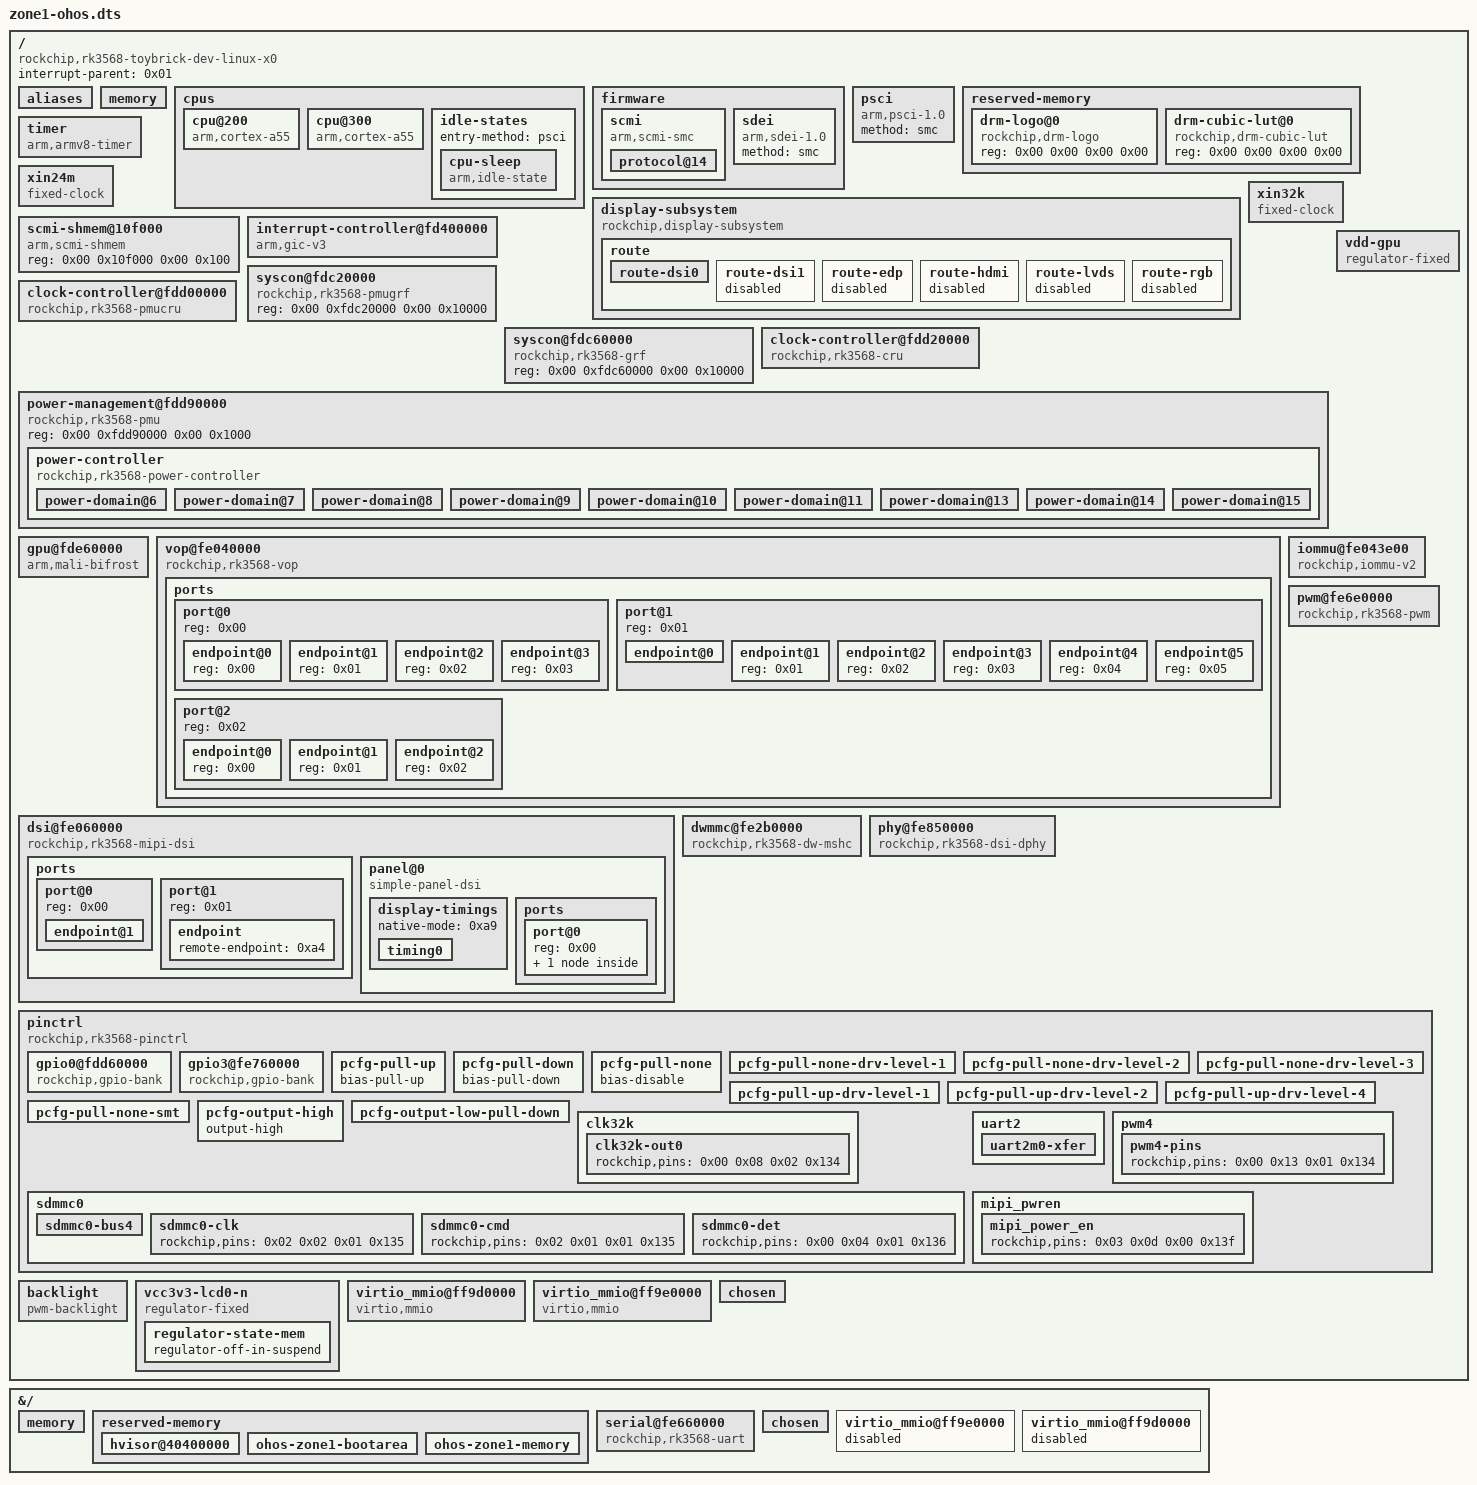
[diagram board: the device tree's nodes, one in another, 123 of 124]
/dts-v1/;

/ {
	interrupt-parent = <0x01>;
	#address-cells = <0x02>;
	#size-cells = <0x02>;
	compatible = "rockchip,rk3568-toybrick-dev-linux-x0\0rockchip,rk3568";

	aliases {
		dsi0 = "/dsi@fe060000";
		gpio3 = "/pinctrl/gpio3@fe760000";
		serial2 = "/serial@fe660000";
		mmc1 = "/dwmmc@fe2b0000";
	};

	memory {
		device_type = "memory";
		reg = <0x00 0x50000000 0x00 0x04000000 
		       0x00 0x10000000 0x00 0x20000000 
			   0x00 0x00 0x00 0x00 
			   0x00 0x00 0x00 0x00 
			   0x00 0x00 0x00 0x00 
			   0x00 0x00 0x00 0x00 
			   0x00 0x00 0x00 0x00 
			   0x00 0x00 0x00 0x00 
			   0x00 0x00 0x00 0x00 
			   0x00 0x00 0x00 0x00 
			   0x00 0x00 0x00 0x00 
			   0x00 0x00 0x00 0x00>;
	};

	cpus {
		#address-cells = <0x02>;
		#size-cells = <0x00>;

		// cpu@0 {
		// 	device_type = "cpu";
		// 	compatible = "arm,cortex-a55";
		// 	reg = <0x00 0x00>;
		// 	clocks = <0x02 0x00>;
		// 	#cooling-cells = <0x02>;
		// 	enable-method = "psci";
		// 	operating-points-v2 = <0x03>;
		// 	cpu-idle-states = <0x04>;
		// 	dynamic-power-coefficient = <0xbb>;
		// 	cpu-supply = <0x05>;
		// 	phandle = <0x1f>;
		// };

		// cpu@100 {
		// 	device_type = "cpu";
		// 	compatible = "arm,cortex-a55";
		// 	reg = <0x00 0x100>;
		// 	#cooling-cells = <0x02>;
		// 	enable-method = "psci";
		// 	operating-points-v2 = <0x03>;
		// 	cpu-idle-states = <0x04>;
		// 	phandle = <0x20>;
		// };

		cpu@200 {
			device_type = "cpu";
			compatible = "arm,cortex-a55";
			reg = <0x00 0x200>;
			#cooling-cells = <0x02>;
			enable-method = "psci";
			operating-points-v2 = <0x03>;
			cpu-idle-states = <0x04>;
			phandle = <0x21>;
		};

		cpu@300 {
			device_type = "cpu";
			compatible = "arm,cortex-a55";
			reg = <0x00 0x300>;
			#cooling-cells = <0x02>;
			enable-method = "psci";
			operating-points-v2 = <0x03>;
			cpu-idle-states = <0x04>;
			phandle = <0x22>;
		};

		idle-states {
			entry-method = "psci";

			cpu-sleep {
				compatible = "arm,idle-state";
				local-timer-stop;
				arm,psci-suspend-param = <0x10000>;
				entry-latency-us = <0x64>;
				exit-latency-us = <0x78>;
				min-residency-us = <0x3e8>;
				phandle = <0x04>;
			};
		};
	};

	firmware {

		scmi {
			compatible = "arm,scmi-smc";
			arm,smc-id = <0x82000010>;
			shmem = <0x19>;
			#address-cells = <0x01>;
			#size-cells = <0x00>;

			protocol@14 {
				reg = <0x14>;
				#clock-cells = <0x01>;
				rockchip,clk-init = <0x41cdb400>;
				phandle = <0x02>;
			};
		};

		sdei {
			compatible = "arm,sdei-1.0";
			method = "smc";
		};
	};

	psci {
		compatible = "arm,psci-1.0";
		method = "smc";
	};

	reserved-memory {
		#address-cells = <0x02>;
		#size-cells = <0x02>;
		ranges;

		drm-logo@0 {
			compatible = "rockchip,drm-logo";
			reg = <0x00 0x00 0x00 0x00>;
			phandle = <0x0f>;
		};

		drm-cubic-lut@0 {
			compatible = "rockchip,drm-cubic-lut";
			reg = <0x00 0x00 0x00 0x00>;
			phandle = <0x10>;
		};
	};

	display-subsystem {
		compatible = "rockchip,display-subsystem";
		memory-region = <0x0f 0x10>;
		memory-region-names = "drm-logo\0drm-cubic-lut";
		ports = <0x11>;

		route {

			route-dsi0 {
				status = "okay";
				logo,uboot = "logo.bmp";
				logo,kernel = "logo_kernel.bmp";
				logo,mode = "center";
				charge_logo,mode = "center";
				connect = <0x13>;
			};

			route-dsi1 {
				status = "disabled";
				logo,uboot = "logo.bmp";
				logo,kernel = "logo_kernel.bmp";
				logo,mode = "center";
				charge_logo,mode = "center";
				connect = <0x14>;
			};

			route-edp {
				status = "disabled";
				logo,uboot = "logo.bmp";
				logo,kernel = "logo_kernel.bmp";
				logo,mode = "center";
				charge_logo,mode = "center";
				connect = <0x15>;
			};

			route-hdmi {
				status = "disabled";
				logo,uboot = "logo.bmp";
				logo,kernel = "logo_kernel.bmp";
				logo,mode = "center";
				charge_logo,mode = "center";
				connect = <0x16>;
			};

			route-lvds {
				status = "disabled";
				logo,uboot = "logo.bmp";
				logo,kernel = "logo_kernel.bmp";
				logo,mode = "center";
				charge_logo,mode = "center";
				connect = <0x17>;
			};

			route-rgb {
				status = "disabled";
				logo,uboot = "logo.bmp";
				logo,kernel = "logo_kernel.bmp";
				logo,mode = "center";
				charge_logo,mode = "center";
				connect = <0x18>;
			};
		};
	};

	timer {
		compatible = "arm,armv8-timer";
		interrupts = <0x01 0x0d 0xf04 0x01 0x0e 0xf04 0x01 0x0b 0xf04 0x01 0x0a 0xf04>;
		arm,no-tick-in-suspend;
	};

	// important
	xin24m {
		compatible = "fixed-clock";
		clock-frequency = <0x16e3600>;
		clock-output-names = "xin24m";
		#clock-cells = <0x00>;
	};

	// important
	xin32k {
		compatible = "fixed-clock";
		clock-frequency = <0x8000>;
		clock-output-names = "xin32k";
		pinctrl-0 = <0x23>;
		pinctrl-names = "default";
		#clock-cells = <0x00>;
	};

	// important
	scmi-shmem@10f000 {
		compatible = "arm,scmi-shmem";
		reg = <0x00 0x10f000 0x00 0x100>;
		phandle = <0x19>;
	};

	interrupt-controller@fd400000 {
		compatible = "arm,gic-v3";
		#interrupt-cells = <0x03>;
		#address-cells = <0x02>;
		#size-cells = <0x02>;
		ranges;
		interrupt-controller;
		reg = <0x00 0xfd400000 0x00 0x10000 0x00 0xfd460000 0x00 0xc0000>;
		interrupts = <0x01 0x09 0x04>;
		phandle = <0x01>;
	};

	
	syscon@fdc20000 {
		compatible = "rockchip,rk3568-pmugrf\0syscon\0simple-mfd";
		reg = <0x00 0xfdc20000 0x00 0x10000>;
		phandle = <0x3c>;
	};

	syscon@fdc60000 {
		compatible = "rockchip,rk3568-grf\0syscon\0simple-mfd";
		reg = <0x00 0xfdc60000 0x00 0x10000>;
		phandle = <0x3b>;
	};

	
	clock-controller@fdd00000 {
		compatible = "rockchip,rk3568-pmucru";
		reg = <0x00 0xfdd00000 0x00 0x1000>;
		rockchip,grf = <0x3b>;
		rockchip,pmugrf = <0x3c>;
		#clock-cells = <0x01>;
		#reset-cells = <0x01>;
		assigned-clocks = <0x3a 0x32>;
		assigned-clock-parents = <0x3a 0x05>;
		phandle = <0x3a>;
	};

	clock-controller@fdd20000 {
		compatible = "rockchip,rk3568-cru";
		reg = <0x00 0xfdd20000 0x00 0x1000>;
		rockchip,grf = <0x3b>;
		#clock-cells = <0x01>;
		#reset-cells = <0x01>;
		assigned-clocks = <0x3a 0x05 0x24 0x106 0x24 0x10b 0x3a 0x01 0x3a 0x2b 0x24 0x03 0x24 0x19b 0x24 0x09 0x24 0x19c 0x24 0x19d 0x24 0x1a1 0x24 0x19e 0x24 0x19f 0x24 0x1a0 0x24 0x04 0x24 0x10d 0x24 0x10e 0x24 0x173 0x24 0x174 0x24 0x175 0x24 0x176 0x24 0xc9 0x24 0xca 0x24 0x06 0x24 0x7e 0x24 0x7f 0x24 0x3d 0x24 0x41 0x24 0x45 0x24 0x49 0x24 0x4d 0x24 0x4d 0x24 0x55 0x24 0x51 0x24 0x5d 0x24 0xdd>;
		assigned-clock-rates = <0x8000 0x11e1a300 0x11e1a300 0xbebc200 0x5f5e100 0x3b9aca00 0x1dcd6500 0x13d92d40 0xee6b280 0x7735940 0x5f5e100 0x3b9aca0 0x2faf080 0x17d7840 0x46cf7100 0x8f0d180 0x5f5e100 0x1dcd6500 0x17d78400 0x8f0d180 0x5f5e100 0x11e1a300 0x8f0d180 0x47868c00 0x17d78400 0x5f5e100 0x46cf7100 0x46cf7100 0x46cf7100 0x46cf7100 0x46cf7100 0x46cf7100 0x46cf7100 0x46cf7100 0x46cf7100 0x1dcd6500>;
		assigned-clock-parents = <0x3a 0x08 0x24 0x04 0x24 0x04>;
		phandle = <0x24>;
	};

	power-management@fdd90000 {
		compatible = "rockchip,rk3568-pmu\0syscon\0simple-mfd";
		reg = <0x00 0xfdd90000 0x00 0x1000>;

		power-controller {
			compatible = "rockchip,rk3568-power-controller";
			#power-domain-cells = <0x01>;
			#address-cells = <0x01>;
			#size-cells = <0x00>;
			phandle = <0x26>;

			power-domain@6 {
				reg = <0x06>;
				clocks = <0x24 0x27 0x24 0x25 0x24 0x26>;
				pm_qos = <0x4e>;
			};

			power-domain@7 {
				reg = <0x07>;
				clocks = <0x24 0x19 0x24 0x1a>;
				pm_qos = <0x4f>;
				#power-domain-cells = <0x00>;
			};

			power-domain@8 {
				reg = <0x08>;
				clocks = <0x24 0xcc 0x24 0xcd>;
				pm_qos = <0x50 0x51 0x52>;
				#power-domain-cells = <0x00>;
			};

			power-domain@9 {
				reg = <0x09>;
				clocks = <0x24 0xda 0x24 0xdb 0x24 0xdc>;
				pm_qos = <0x53 0x54 0x55>;
				#power-domain-cells = <0x00>;
			};

			power-domain@10 {
				reg = <0x0a>;
				clocks = <0x24 0xf1 0x24 0xf2>;
				pm_qos = <0x56 0x57 0x58 0x59 0x5a 0x5b>;
				#power-domain-cells = <0x00>;
			};

			power-domain@11 {
				reg = <0x0b>;
				clocks = <0x24 0xed>;
				pm_qos = <0x5c>;
				#power-domain-cells = <0x00>;
			};

			power-domain@13 {
				clocks = <0x24 0x107>;
				reg = <0x0d>;
				pm_qos = <0x5d>;
				#power-domain-cells = <0x00>;
			};

			power-domain@14 {
				reg = <0x0e>;
				clocks = <0x24 0x102>;
				pm_qos = <0x5e 0x5f 0x60>;
				#power-domain-cells = <0x00>;
			};

			power-domain@15 {
				reg = <0x0f>;
				clocks = <0x24 0x7f>;
				pm_qos = <0x61 0x62 0x63 0x64 0x65 0x66 0x67 0x68>;
				#power-domain-cells = <0x00>;
			};
		};
	};

	vdd-gpu {
		compatible = "regulator-fixed";
		regulator-name = "vdd_gpu";
		regulator-always-on;
		regulator-boot-on;
		regulator-min-microvolt = <0xdbba0>;
		regulator-max-microvolt = <0xdbba0>;
		phandle = <0x71>;
	};

	gpu@fde60000 {
		compatible = "arm,mali-bifrost";
		reg = <0x00 0xfde60000 0x00 0x4000>;
		interrupts = <0x00 0x27 0x04 0x00 0x29 0x04 0x00 0x28 0x04>;
		interrupt-names = "GPU\0MMU\0JOB";
		upthreshold = <0x28>;
		downdifferential = <0x0a>;
		clocks = <0x02 0x01 0x24 0x1b>;
		clock-names = "clk_mali\0clk_gpu";
		power-domains = <0x26 0x07>;
		#cooling-cells = <0x02>;
		status = "okay";
		mali-supply = <0x71>;
		phandle = <0x11e>;
	};

	vop@fe040000 {
		compatible = "rockchip,rk3568-vop";
		reg = <0x00 0xfe040000 0x00 0x3000 0x00 0xfe044000 0x00 0x1000>;
		reg-names = "regs\0gamma_lut";
		interrupts = <0x00 0x94 0x04>;
		clocks = <0x24 0xdd 0x24 0xde 0x24 0xdf 0x24 0xe0 0x24 0xe1>;
		clock-names = "aclk_vop\0hclk_vop\0dclk_vp0\0dclk_vp1\0dclk_vp2";
		rockchip,aclk-normal-mode-rates = <0x179a7b00>;
		rockchip,aclk-advanced-mode-rates = <0x1dcd6500>;
		iommus = <0x95>;
		power-domains = <0x26 0x09>;
		rockchip,grf = <0x3b>;
		status = "okay";
		assigned-clocks = <0x24 0xdf 0x24 0xe0>;
		assigned-clock-parents = <0x3a 0x02 0x24 0x05>;
		disable-afbc-win;

			ports {
			#address-cells = <0x01>;
			#size-cells = <0x00>;
			phandle = <0x11>;

			port@0 {
				reg = <0x00>;
				#address-cells = <0x01>;
				#size-cells = <0x00>;

				endpoint@0 {
					reg = <0x00>;
					phandle = <0xa3>;
				};

				endpoint@1 {
					reg = <0x01>;
					phandle = <0x14>;
				};

				endpoint@2 {
					reg = <0x02>;
					phandle = <0x15>;
				};

				endpoint@3 {
					reg = <0x03>;
					phandle = <0x16>;
				};
			};

			port@1 {
				reg = <0x01>;
				#address-cells = <0x01>;
				#size-cells = <0x00>;

				endpoint@0 {
					reg = <0x00>;
					remote-endpoint = <0x9a>;
					phandle = <0x13>;
				};

				endpoint@1 {
					reg = <0x01>;
					phandle = <0xab>;
				};

				endpoint@2 {
					reg = <0x02>;
					phandle = <0xb8>;
				};

				endpoint@3 {
					reg = <0x03>;
					phandle = <0xb6>;
				};

				endpoint@4 {
					reg = <0x04>;
					phandle = <0x17>;
				};

				endpoint@5 {
					reg = <0x05>;
					phandle = <0x38>;
				};
			};

			port@2 {
				reg = <0x02>;
				#address-cells = <0x01>;
				#size-cells = <0x00>;

				endpoint@0 {
					reg = <0x00>;
					phandle = <0x35>;
				};

				endpoint@1 {
					reg = <0x01>;
					phandle = <0x18>;
				};

				endpoint@2 {
					reg = <0x02>;
					phandle = <0x39>;
				};
			};
		};
	};

	iommu@fe043e00 {
		compatible = "rockchip,iommu-v2";
		reg = <0x00 0xfe043e00 0x00 0x100 0x00 0xfe043f00 0x00 0x100>;
		interrupts = <0x00 0x94 0x04>;
		interrupt-names = "vop_mmu";
		clocks = <0x24 0xdd 0x24 0xde>;
		clock-names = "aclk\0iface";
		#iommu-cells = <0x00>;
		rockchip,disable-device-link-resume;
		status = "okay";
		phandle = <0x95>;
	};

	dsi@fe060000 {
		compatible = "rockchip,rk3568-mipi-dsi";
		reg = <0x00 0xfe060000 0x00 0x10000>;
		interrupts = <0x00 0x44 0x04>;
		clock-names = "pclk\0hclk";
		clocks = <0x24 0xe8 0x24 0xda>;
		phy-names = "dphy";
		phys = <0x34>;
		power-domains = <0x26 0x09>;
		reset-names = "apb";
		resets = <0x24 0x110>;
		rockchip,grf = <0x3b>;
		#address-cells = <0x01>;
		#size-cells = <0x00>;
		status = "okay";

		ports {
			#address-cells = <0x01>;
			#size-cells = <0x00>;

			port@0 {
				reg = <0x00>;
				#address-cells = <0x01>;
				#size-cells = <0x00>;

				endpoint@1 {
					reg = <0x01>;
					remote-endpoint = <0x13>;
					status = "okay";
					phandle = <0x9a>;
				};
			};

			port@1 {
				reg = <0x01>;

				endpoint {
					remote-endpoint = <0xa4>;
					phandle = <0xaa>;
				};
			};
		};

		panel@0 {
			status = "okay";
			compatible = "simple-panel-dsi";
			reg = <0x00>;
			backlight = <0xa5>;
			reset-delay-ms = <0x64>;
			enable-delay-ms = <0x78>;
			prepare-delay-ms = <0x02>;
			unprepare-delay-ms = <0x14>;
			disable-delay-ms = <0x32>;
			dsi,flags = <0xa03>;
			dsi,format = <0x00>;
			dsi,lanes = <0x04>;
			panel-init-sequence = <0x5640111 0x390004ff 0x98810315 0x20100 0x15000202 0x150002 0x3721500 0x2040015 0x20500 0x15000206 0x9150002 0x7001500 0x2080015 0x20901 0x1500020a 0x150002 0xb001500 0x20c0115 0x20d00 0x1500020e 0x150002 0xf001500 0x2100015 0x21100 0x15000212 0x150002 0x13001500 0x2140015 0x21500 0x15000216 0x150002 0x17001500 0x2180015 0x21900 0x1500021a 0x150002 0x1b001500 0x21c0015 0x21d00 0x1500021e 0x40150002 0x1f801500 0x2200515 0x22102 0x15000222 0x150002 0x23001500 0x2240015 0x22500 0x15000226 0x150002 0x27001500 0x2283315 0x22902 0x1500022a 0x150002 0x2b001500 0x22c0015 0x22d00 0x1500022e 0x150002 0x2f001500 0x2300015 0x23100 0x15000232 0x150002 0x33001500 0x2340415 0x23500 0x15000236 0x150002 0x37001500 0x2383c15 0x23900 0x1500023a 0x40150002 0x3b401500 0x23c0015 0x23d00 0x1500023e 0x150002 0x3f001500 0x2400015 0x24100 0x15000242 0x150002 0x43001500 0x2440015 0x25001 0x15000251 0x23150002 0x52451500 0x2536715 0x25489 0x15000255 0xab150002 0x56011500 0x2572315 0x25845 0x15000259 0x67150002 0x5a891500 0x25bab15 0x25ccd 0x1500025d 0xef150002 0x5e111500 0x25f0115 0x26000 0x15000261 0x15150002 0x62141500 0x2630e15 0x2640f 0x15000265 0xc150002 0x660d1500 0x2670615 0x26802 0x15000269 0x2150002 0x6a021500 0x26b0215 0x26c02 0x1500026d 0x2150002 0x6e071500 0x26f0215 0x27002 0x15000271 0x2150002 0x72021500 0x2730215 0x27402 0x15000275 0x1150002 0x76001500 0x2771415 0x27815 0x15000279 0xe150002 0x7a0f1500 0x27b0c15 0x27c0d 0x1500027d 0x6150002 0x7e021500 0x27f0215 0x28002 0x15000281 0x2150002 0x82021500 0x2830215 0x28407 0x15000285 0x2150002 0x86021500 0x2870215 0x28802 0x15000289 0x2150002 0x8a023900 0x4ff9881 0x4150002 0x6c151500 0x26e2a15 0x26f33 0x1500023a 0x94150002 0x8d1a1500 0x287ba15 0x22676 0x150002b2 0xd1150002 0xb5063900 0x4ff9881 0x1150002 0x220a1500 0x2310015 0x24013 0x15000253 0x84150002 0x558f1500 0x250ae15 0x251ae 0x15000260 0x28150002 0xa00f1500 0x2a11b15 0x2a228 0x150002a3 0x12150002 0xa4151500 0x2a52815 0x2a61b 0x150002a7 0x1e150002 0xa8791500 0x2a91b15 0x2aa27 0x150002ab 0x69150002 0xac191500 0x2ad1815 0x2ae4c 0x150002af 0x21150002 0xb0281500 0x2b15215 0x2b265 0x150002c0 0x4150002 0xc11b1500 0x2c22715 0x2c313 0x150002c4 0x15150002 0xc5281500 0x2c61c15 0x2c71e 0x150002c8 0x79150002 0xc91a1500 0x2ca2715 0x2cb69 0x150002cc 0x1a150002 0xcd181500 0x2ce4c15 0x2cf21 0x150002d0 0x27150002 0xd1521500 0x2d26515 0x2d33f 0x390004ff 0x98810005 0x32012915 0x23500>;
			panel-exit-sequence = <0x5320128 0x5c80110>;
			power-supply = <0xa6>;
			init-delay-ms = <0x14>;
			pinctrl-names = "default";
			pinctrl-0 = <0xa7>;
			enable-gpios = <0xa8 0x0d 0x00>;
			width-mm = <0x44>;
			height-mm = <0x79>;
			pnel-type = <0x05>;

			display-timings {
				native-mode = <0xa9>;

				timing0 {
					clock-frequency = <0x47868c0>;
					hactive = <0x2d0>;
					vactive = <0x500>;
					hfront-porch = <0x28>;
					hsync-len = <0x0a>;
					hback-porch = <0x28>;
					vfront-porch = <0x0a>;
					vsync-len = <0x24>;
					vback-porch = <0x0f>;
					hsync-active = <0x00>;
					vsync-active = <0x00>;
					de-active = <0x00>;
					pixelclk-active = <0x00>;
					phandle = <0xa9>;
				};
			};

			ports {
				#address-cells = <0x01>;
				#size-cells = <0x00>;

				port@0 {
					reg = <0x00>;

					endpoint {
						remote-endpoint = <0xaa>;
						phandle = <0xa4>;
					};
				};
			};
		};
	};

	dwmmc@fe2b0000 {
		compatible = "rockchip,rk3568-dw-mshc\0rockchip,rk3288-dw-mshc";
		reg = <0x00 0xfe2b0000 0x00 0x4000>;
		interrupts = <0x00 0x62 0x04>;
		clocks = <0x24 0xb0 0x24 0xb1 0x24 0x18a 0x24 0x18b>;
		clock-names = "biu\0ciu\0ciu-drive\0ciu-sample";
		fifo-depth = <0x100>;
		max-frequency = <0x8f0d180>;
		resets = <0x24 0xd4>;
		reset-names = "reset";
		status = "okay";
		supports-sd;
		bus-width = <0x04>;
		cap-mmc-highspeed;
		cap-sd-highspeed;
		disable-wp;
		no-1-8-v;
		pinctrl-names = "default";
		pinctrl-0 = <0xc5 0xc6 0xc7 0xc8>;
	};

	pwm@fe6e0000 {
		compatible = "rockchip,rk3568-pwm\0rockchip,rk3328-pwm";
		reg = <0x00 0xfe6e0000 0x00 0x10>;
		interrupts = <0x00 0x53 0x04>;
		clocks = <0x24 0x15a 0x24 0x159>;
		clock-names = "pwm\0pclk";
		pinctrl-0 = <0x110>;
		pinctrl-names = "active";
		#pwm-cells = <0x03>;
		status = "okay";
		phandle = <0x154>;
	};

	phy@fe850000 {
		compatible = "rockchip,rk3568-dsi-dphy\0rockchip,rk3568-video-phy";
		reg = <0x00 0xfe850000 0x00 0x10000 0x00 0xfe060000 0x00 0x10000>;
		reg-names = "phy\0host";
		clocks = <0x3a 0x17 0x24 0x17a 0x24 0xe8>;
		clock-names = "ref\0pclk\0pclk_host";
		#clock-cells = <0x00>;
		resets = <0x24 0x1bb>;
		reset-names = "apb";
		power-domains = <0x26 0x09>;
		#phy-cells = <0x00>;
		status = "okay";
		phandle = <0x34>;
	};

	pinctrl {
		compatible = "rockchip,rk3568-pinctrl";
		rockchip,grf = <0x3b>;
		rockchip,pmu = <0x3c>;
		#address-cells = <0x02>;
		#size-cells = <0x02>;
		ranges;

		gpio0@fdd60000 {
			compatible = "rockchip,gpio-bank";
			reg = <0x00 0xfdd60000 0x00 0x100>;
			interrupts = <0x00 0x21 0x04>;
			clocks = <0x3a 0x2e 0x3a 0x0c>;
			gpio-controller;
			#gpio-cells = <0x02>;
			interrupt-controller;
			#interrupt-cells = <0x02>;
			phandle = <0x3f>;
		};

		gpio3@fe760000 {
			compatible = "rockchip,gpio-bank";
			reg = <0x00 0xfe760000 0x00 0x100>;
			interrupts = <0x00 0x24 0x04>;
			clocks = <0x24 0x167 0x24 0x168>;
			gpio-controller;
			#gpio-cells = <0x02>;
			interrupt-controller;
			#interrupt-cells = <0x02>;
			phandle = <0xa8>;
		};

		pcfg-pull-up {
			bias-pull-up;
			phandle = <0x136>;
		};

		pcfg-pull-down {
			bias-pull-down;
			phandle = <0x13e>;
		};

		pcfg-pull-none {
			bias-disable;
			phandle = <0x134>;
		};

		pcfg-pull-none-drv-level-1 {
			bias-disable;
			drive-strength = <0x01>;
			phandle = <0x138>;
		};

		pcfg-pull-none-drv-level-2 {
			bias-disable;
			drive-strength = <0x02>;
			phandle = <0x137>;
		};

		pcfg-pull-none-drv-level-3 {
			bias-disable;
			drive-strength = <0x03>;
			phandle = <0x13d>;
		};

		pcfg-pull-up-drv-level-1 {
			bias-pull-up;
			drive-strength = <0x01>;
			phandle = <0x13c>;
		};

		pcfg-pull-up-drv-level-2 {
			bias-pull-up;
			drive-strength = <0x02>;
			phandle = <0x135>;
		};

		pcfg-pull-up-drv-level-4 {
			bias-pull-up;
			drive-strength = <0x04>;
			phandle = <0x13a>;
		};

		pcfg-pull-none-smt {
			bias-disable;
			input-schmitt-enable;
			phandle = <0x139>;
		};

		pcfg-output-high {
			output-high;
			phandle = <0x13f>;
		};

		pcfg-output-low-pull-down {
			output-low;
			bias-pull-down;
			phandle = <0x13b>;
		};

		clk32k {

			clk32k-out0 {
				rockchip,pins = <0x00 0x08 0x02 0x134>;
				phandle = <0x23>;
			};
		};

		sdmmc0 {

			sdmmc0-bus4 {
				rockchip,pins = <0x01 0x1d 0x01 0x135 0x01 0x1e 0x01 0x135 0x01 0x1f 0x01 0x135 0x02 0x00 0x01 0x135>;
				phandle = <0xc5>;
			};

			sdmmc0-clk {
				rockchip,pins = <0x02 0x02 0x01 0x135>;
				phandle = <0xc6>;
			};

			sdmmc0-cmd {
				rockchip,pins = <0x02 0x01 0x01 0x135>;
				phandle = <0xc7>;
			};

			sdmmc0-det {
				rockchip,pins = <0x00 0x04 0x01 0x136>;
				phandle = <0xc8>;
			};
		};

		uart2 {

			uart2m0-xfer {
				rockchip,pins = <0x00 0x18 0x01 0x136 0x00 0x19 0x01 0x136>;
				phandle = <0x107>;
			};
		};

		pwm4 {

			pwm4-pins {
				rockchip,pins = <0x00 0x13 0x01 0x134>;
				phandle = <0x110>;
			};
		};

		mipi_pwren {

			mipi_power_en {
				rockchip,pins = <0x03 0x0d 0x00 0x13f>;
				phandle = <0xa7>;
			};
		};
	};

	backlight {
		compatible = "pwm-backlight";
		pwms = <0x154 0x00 0x61a8 0x00>;
		brightness-levels = <0x00 0x14 0x14 0x15 0x15 0x16 0x16 0x17 0x17 0x18 0x18 0x19 0x19 0x1a 0x1a 0x1b 0x1b 0x1c 0x1c 0x1d 0x1d 0x1e 0x1e 0x1f 0x1f 0x20 0x20 0x21 0x21 0x22 0x22 0x23 0x23 0x24 0x24 0x25 0x25 0x26 0x26 0x27 0x28 0x29 0x2a 0x2b 0x2c 0x2d 0x2e 0x2f 0x30 0x31 0x32 0x33 0x34 0x35 0x36 0x37 0x38 0x39 0x3a 0x3b 0x3c 0x3d 0x3e 0x3f 0x40 0x41 0x42 0x43 0x44 0x45 0x46 0x47 0x48 0x49 0x4a 0x4b 0x4c 0x4d 0x4e 0x4f 0x50 0x51 0x52 0x53 0x54 0x55 0x56 0x57 0x58 0x59 0x5a 0x5b 0x5c 0x5d 0x5e 0x5f 0x60 0x61 0x62 0x63 0x64 0x65 0x66 0x67 0x68 0x69 0x6a 0x6b 0x6c 0x6d 0x6e 0x6f 0x70 0x71 0x72 0x73 0x74 0x75 0x76 0x77 0x78 0x79 0x7a 0x7b 0x7c 0x7d 0x7e 0x7f 0x80 0x81 0x82 0x83 0x84 0x85 0x86 0x87 0x88 0x89 0x8a 0x8b 0x8c 0x8d 0x8e 0x8f 0x90 0x91 0x92 0x93 0x94 0x95 0x96 0x97 0x98 0x99 0x9a 0x9b 0x9c 0x9d 0x9e 0x9f 0xa0 0xa1 0xa2 0xa3 0xa4 0xa5 0xa6 0xa7 0xa8 0xa9 0xaa 0xab 0xac 0xad 0xae 0xaf 0xb0 0xb1 0xb2 0xb3 0xb4 0xb5 0xb6 0xb7 0xb8 0xb9 0xba 0xbb 0xbc 0xbd 0xbe 0xbf 0xc0 0xc1 0xc2 0xc3 0xc4 0xc5 0xc6 0xc7 0xc8 0xc9 0xca 0xcb 0xcc 0xcd 0xce 0xcf 0xd0 0xd1 0xd2 0xd3 0xd4 0xd5 0xd6 0xd7 0xd8 0xd9 0xda 0xdb 0xdc 0xdd 0xde 0xdf 0xe0 0xe1 0xe2 0xe3 0xe4 0xe5 0xe6 0xe7 0xe8 0xe9 0xea 0xeb 0xec 0xed 0xee 0xef 0xf0 0xf1 0xf2 0xf3 0xf4 0xf5 0xf6 0xf7 0xf8 0xf9 0xfa 0xfb 0xfc 0xfd 0xfe 0xff>;
		default-brightness-level = <0xc8>;
		status = "okay";
		phandle = <0xa5>;
	};

	vcc3v3-lcd0-n {
		compatible = "regulator-fixed";
		regulator-name = "vcc3v3_lcd0_n";
		regulator-boot-on;
		gpio = <0x3f 0x17 0x00>;
		enable-active-high;
		phandle = <0xa6>;

		regulator-state-mem {
			regulator-off-in-suspend;
		};
	};

	virtio_mmio@ff9d0000 {
		dma-coherent;
		interrupt-parent = <0x01>;
		interrupts = <0x00 0x6e 0x01>;
		reg = <0x00 0xff9d0000 0x00 0x200>;
		compatible = "virtio,mmio";
	};

	virtio_mmio@ff9e0000 {
		dma-coherent;
		interrupt-parent = <0x01>;
		interrupts = <0x00 0x6c 0x01>;
		reg = <0x00 0xff9e0000 0x00 0x200>;
		compatible = "virtio,mmio";
	};

	chosen {
		bootargs = "earlycon=virtio,mmio,0xff9d0000 console=hvc0 ignore_loglevel loglevel=8 initcall_debug clk_ignore_unused pd_ignore_unused bootslots=0 ohos.boot.eng_mode=on root=PARTUUID=614e0000-0000 hardware=rk3568 default_boot_device=fe2b0000.dwmmc rw rootwait ohos.required_mount.system=/dev/block/platform/fe2b0000.dwmmc/by-name/system@/usr@ext4@ro,barrier=1@wait,required ohos.required_mount.vendor=/dev/block/platform/fe2b0000.dwmmc/by-name/vendor@/vendor@ext4@ro,barrier=1@wait,required ohos.required_mount.misc=/dev/block/platform/fe2b0000.dwmmc/by-name/misc@none@none@none@wait,required ohos.required_mount.bootctrl=/dev/block/platform/fe2b0000.dwmmc/by-name/bootctrl@none@none@none@wait,required";
		stdout-path = "/virtio_mmio@ff9d0000";
		linux,initrd-start = <0x00 0x50200000>;
		linux,initrd-end = <0x00 0x50600000>;
	};
};


// 请勿删除这段注释。裸启动修改集中放这里。需要启用时取消整段注释；需要关闭时注释整段。（已经通过反编译确定改动有效了）
&{/} {
	memory {
		device_type = "memory";
		reg = <0x00 0x200000 0x00 0x8200000
		       0x00 0x9400000 0x00 0x76c00000
		       0x00 0x00 0x00 0x00
		       0x00 0x00 0x00 0x00
		       0x00 0x00 0x00 0x00
		       0x00 0x00 0x00 0x00
		       0x00 0x00 0x00 0x00
		       0x00 0x00 0x00 0x00
		       0x00 0x00 0x00 0x00
		       0x00 0x00 0x00 0x00
		       0x00 0x00 0x00 0x00
		       0x00 0x00 0x00 0x00>;
	};

	reserved-memory {
		#size-cells = <0x02>;
		ranges;
		#address-cells = <0x02>;

		hvisor@40400000 {
			no-map;
			reg = <0x00 0x40400000 0x00 0x4900000>;
		};

		ohos-zone1-bootarea {
			no-map;
			reg = <0x00 0x50000000 0x00 0x04000000>;
			// [0x5000_0000, 0x5020_0000), 2 MiB, device-tree-blob
			// [0x5020_0000, 0x5060_0000), 4 MiB, ramdisk
			// [0x5060_0000, 0x5360_0000), 48 MiB, kernel
			// [0x5360_0000, 0x5400_0000) free
		};

		ohos-zone1-memory {
			no-map;
			reg = <0x00 0x10000000 0x00 0x20000000>;
		};
	};

	serial@fe660000 {
		compatible = "rockchip,rk3568-uart\0snps,dw-apb-uart";
		reg = <0x00 0xfe660000 0x00 0x100>;
		interrupts = <0x00 0x76 0x04>;
		clocks = <0x24 0x123 0x24 0x120>;
		clock-names = "baudclk\0apb_pclk";
		dmas = <0x48 0x04 0x48 0x05>;
		pinctrl-0 = <0x107>;
		pinctrl-names = "default";
		reg-io-width = <0x04>;
		reg-shift = <0x02>;
		status = "okay";
	};

	chosen {
		bootargs = "earlycon=uart8250,mmio32,0xfe660000 console=ttyS2,1500000n8 enforcing=0 ignore_loglevel loglevel=8 initcall_debug clk_ignore_unused pd_ignore_unused bootslots=0 ohos.boot.eng_mode=on root=PARTUUID=614e0000-0000 hardware=rk3568 default_boot_device=fe2b0000.dwmmc rw rootwait ohos.required_mount.system=/dev/block/platform/fe2b0000.dwmmc/by-name/system@/usr@ext4@ro,barrier=1@wait,required ohos.required_mount.vendor=/dev/block/platform/fe2b0000.dwmmc/by-name/vendor@/vendor@ext4@ro,barrier=1@wait,required ohos.required_mount.misc=/dev/block/platform/fe2b0000.dwmmc/by-name/misc@none@none@none@wait,required ohos.required_mount.bootctrl=/dev/block/platform/fe2b0000.dwmmc/by-name/bootctrl@none@none@none@wait,required";
		linux,initrd-start = <0x00 0xa200000>;
		linux,initrd-end = <0x00 0xa600000>;
	};
	
	virtio_mmio@ff9e0000 {
		status = "disabled";
	};

	virtio_mmio@ff9d0000 {
		status = "disabled";
	};
};
